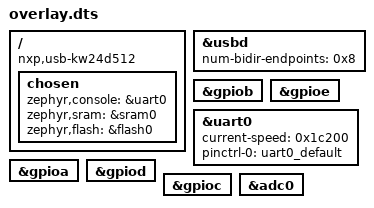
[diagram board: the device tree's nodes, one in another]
/ {
	compatible = "nxp,usb-kw24d512", "nxp,kw24d512", "nxp,kw2xd";
	chosen {
		zephyr,console = &uart0;
		zephyr,sram = &sram0;
		zephyr,flash = &flash0;
	};
};
&usbd{
	num-bidir-endpoints = < 0x8 >;
	status = "okay";
};
&gpiob{
	status = "okay";
};
&gpioe{
	status = "okay";
};
&uart0{
	status = "okay";
	current-speed = < 0x1c200 >;
	pinctrl-0 = < &uart0_default >;
	pinctrl-names = "default";
};
&gpioa{
	status = "okay";
};
&gpiod{
	status = "okay";
};
&gpioc{
	status = "okay";
};
&adc0{
	status = "okay";
};
